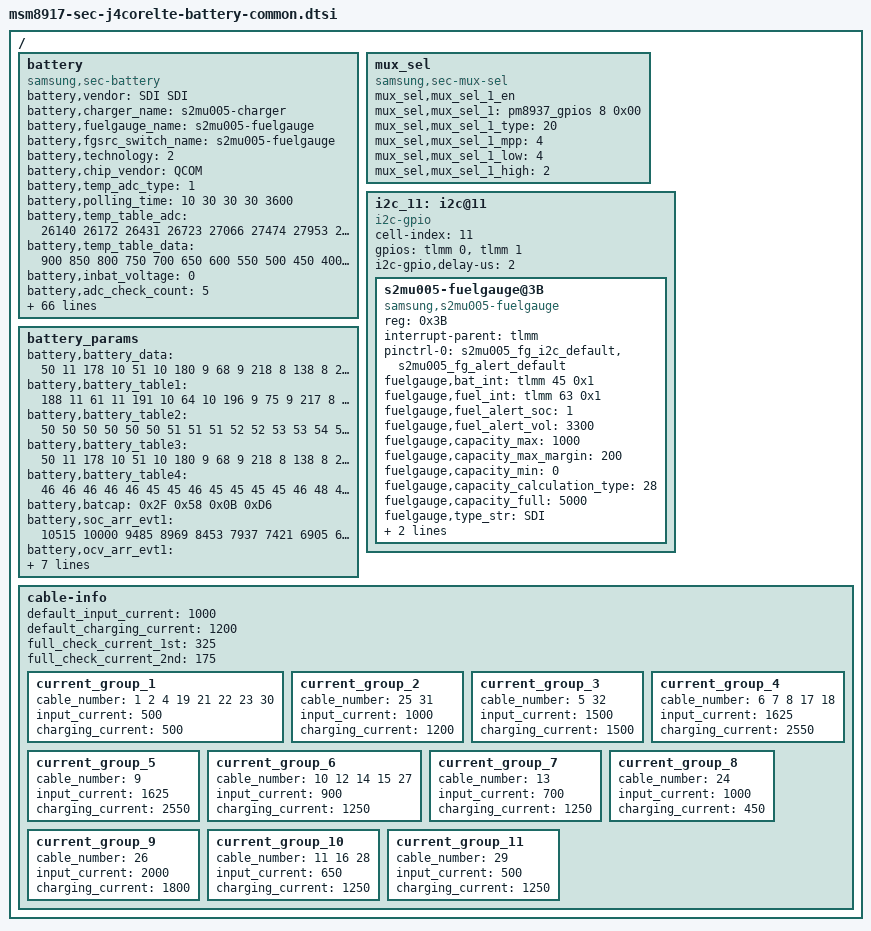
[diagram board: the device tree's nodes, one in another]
/* Copyright (c) 2015, The Linux Foundation. All rights reserved.
 *
 * This program is free software; you can redistribute it and/or modify
 * it under the terms of the GNU General Public License version 2 and
 * only version 2 as published by the Free Software Foundation.
 *
 * This program is distributed in the hope that it will be useful,
 * but WITHOUT ANY WARRANTY; without even the implied warranty of
 * MERCHANTABILITY or FITNESS FOR A PARTICULAR PURPOSE.  See the
 * GNU General Public License for more details.
 */

/ {
	battery {
		status = "okay";
		compatible = "samsung,sec-battery";
		battery,vendor = "SDI SDI";
		battery,charger_name = "s2mu005-charger";
		battery,fuelgauge_name = "s2mu005-fuelgauge";
		battery,fgsrc_switch_name = "s2mu005-fuelgauge"; /* Fuelgauge voltage source */
		battery,technology = <2>; /* POWER_SUPPLY_TECHNOLOGY_LION */
		battery,chip_vendor = "QCOM";
		
		battery,temp_adc_type = <1>; /* SEC_BATTERY_ADC_TYPE_AP */

		battery,polling_time = <10 30 30 30 3600>;

		battery,temp_table_adc = <26140 26172 26431 26723 27066 27474 27953 28492 29136 29862 30583 31973 32751 33835 34847 35867 36897 37876 38713 39527 40193 40751 41156>;
		battery,temp_table_data = <900 850 800 750 700 650 600 550 500 450 400 350 300 250 200 150 100 50 0 (-50) (-100) (-150) (-200)>;

		battery,inbat_voltage = <0>;

		battery,adc_check_count = <5>;

		battery,cable_check_type = <4>; /* SEC_BATTERY_CABLE_CHECK_PSY */
		battery,cable_source_type = <1>; /* SEC_BATTERY_CABLE_SOURCE_EXTERNAL */
		battery,polling_type = <1>; /* SEC_BATTERY_MONITOR_ALARM */
		battery,monitor_initial_count = <0>;

		battery,battery_check_type = <0>; /* SEC_BATTERY_CHECK_NONE */
		battery,check_count = <0>;

		battery,check_adc_max = <1440>;
		battery,check_adc_min = <0>;

		battery,ovp_uvlo_check_type = <3>; /* SEC_BATTERY_OVP_UVLO_CHGPOLLING */

		battery,thermal_source = <2>; /* SEC_BATTERY_THERMAL_SOURCE_ADC */
		battery,chg_thermal_source = <0>;
		battery,chg_temp_check = <0>;

		battery,adc_channels = <0x13>;
		battery,channel_names = "adc-temp";
		battery,channel_cells = <1>;

		battery,temp_check_type = <2>; /* SEC_BATTERY_TEMP_CHECK_TEMP */
		battery,temp_check_count = <1>;
		battery,temp_highlimit_threshold_normal = <800>;
		battery,temp_highlimit_recovery_normal = <750>;
		battery,temp_high_threshold_normal = <500>;
		battery,temp_high_recovery_normal = <450>;
		battery,temp_low_threshold_normal = <0>;
		battery,temp_low_recovery_normal = <50>;
		battery,temp_highlimit_threshold_lpm = <800>;
		battery,temp_highlimit_recovery_lpm = <750>;
		battery,temp_high_threshold_lpm = <500>;
		battery,temp_high_recovery_lpm = <450>;
		battery,temp_low_threshold_lpm = <0>;
		battery,temp_low_recovery_lpm = <50>;

		battery,full_check_type = <2>; /* SEC_BATTERY_FULLCHARGED_FG_CURRENT */
		battery,full_check_type_2nd = <2>; /* SEC_BATTERY_FULLCHARGED_FG_CURRENT */
		battery,full_check_count = <1>;
		battery,chg_gpio_full_check = <0>;
		battery,chg_polarity_full_check = <1>;

		/* SEC_BATTERY_FULL_CONDITION_SOC |
		   SEC_BATTERY_FULL_CONDITION_NOTIMEFULL |
		   SEC_BATTERY_FULL_CONDITION_VCELL */
		battery,full_condition_type = <13>;
		battery,full_condition_soc = <93>;
		battery,full_condition_vcell = <4290>;

		battery,recharge_check_count = <2>;
		battery,recharge_condition_type = <4>; /* SEC_BATTERY_RECHARGE_CONDITION_VCELL */
		battery,recharge_condition_soc = <98>;
		battery,recharge_condition_vcell = <4250>;

		battery,expired_time = <18600>;      /* 230min + 80min margin */
		battery,recharging_expired_time = <5400>;
		battery,standard_curr = <1034>; /* IP < CP */

		battery,swelling_high_temp_block = <410>;
		battery,swelling_high_temp_recov = <390>;

		battery,swelling_low_temp_2step_mode = <1>;
		battery,swelling_low_temp_block_1st = <150>;
		battery,swelling_low_temp_recov_1st = <200>;
		battery,swelling_low_temp_block_2nd = <50>;
		battery,swelling_low_temp_recov_2nd = <100>;

		battery,swelling_low_temp_current = <750>;	/* 0.3C */
		battery,swelling_low_temp_topoff = <175>;	/* 0.05C */
		battery,swelling_high_temp_current = <1150>;	/* 0.45C */
		battery,swelling_high_temp_topoff = <175>;	/* 0.05C */

		battery,swelling_drop_float_voltage = <4150>;
		battery,swelling_high_rechg_voltage = <4000>;
		battery,swelling_low_rechg_voltage = <4000>;

		battery,siop_input_limit_current = <1000>;
		battery,siop_charging_limit_current = <1000>;

		battery,chg_float_voltage = <4350>;
		battery,mivr_voltage = <1>; /* 0:  4200, 1 : 4300, 2 : 4400 ..... 7: 4900 */

		battery,cisd_max_voltage_thr = <5000>;

		/* cycle(week), chg_float_voltage, recharge_condition_vcell, full_condition_vcell, full_condition_soc*/
		battery,age_data = <0 4350 4250 4250 93	/*4.35*/
				200 4330 4230 4230 92	/*4.33*/
				250 4310 4210 4210 91	/*4.31*/
				300 4290 4190 4190 90	/*4.29*/
				1000 4240 4140 4140 89	/*4.24*/
				>;

		qcom,sec-battery-vadc = <&pm8937_vadc>;
	};


	mux_sel {
		compatible = "samsung,sec-mux-sel";
		mux_sel,mux_sel_1_en;
		mux_sel,mux_sel_1 = <&pm8937_gpios 8 0x00>;
		mux_sel,mux_sel_1_type = <20>; /* BATT_THM_MUX_SEL | AP_THM_MUX_SEL */
		mux_sel,mux_sel_1_mpp = <4>; /* SEC_MPP4_MUX_SEL */
		mux_sel,mux_sel_1_low = <4>; /* SEC_MUX_SEL_AP_THM */
		mux_sel,mux_sel_1_high = <2>; /* SEC_MUX_SEL_BATT_THM */
	};

	i2c_11: i2c@11 {
		cell-index = <11>;
		compatible = "i2c-gpio";
		gpios = <&tlmm 0 0	/* sda */
			&tlmm 1 0	/* scl */
			>;
		i2c-gpio,delay-us = <2>;
		#address-cells = <1>;
		#size-cells = <0>;

		s2mu005-fuelgauge@3B{
			status = "okay";
			compatible = "samsung,s2mu005-fuelgauge";
			reg = <0x3B>;
			interrupt-parent = <&tlmm>;
			pinctrl-names = "default";
			pinctrl-0 = <&s2mu005_fg_i2c_default &s2mu005_fg_alert_default>;
			fuelgauge,bat_int = <&tlmm 45 0x1>;
			fuelgauge,fuel_int = <&tlmm 63 0x1>;
			fuelgauge,fuel_alert_soc = <1>;
			fuelgauge,fuel_alert_vol = <3300>;
			fuelgauge,capacity_max = <1000>;
			fuelgauge,capacity_max_margin = <200>;
			fuelgauge,capacity_min = <0>;
			fuelgauge,capacity_calculation_type = <28>;
			fuelgauge,capacity_full = <5000>; /* battery capacity */
			fuelgauge,type_str = "SDI";
			fuelgauge,model_type = <1>;
			fuelgauge,fg_log_enable = <1>;
		};
	};
	
	battery_params {
			battery,battery_data =
			<
				/***** battery data for 4.35 *****/
				/* battery,battery_table3 */
				50 11 178 10 51 10 180 9 68 9
				218 8 138 8 247 7 190 7 116 7
				11 7 194 6 146 6 109 6 80 6
				57 6 32 6 247 5 190 5 133 5
				54 5 235 0 235 8 124 8 13 8
				158 7 47 7 192 6 80 6 225 5
				114 5 3 5 148 4 37 4 181 3
				70 3 215 2 104 2 249 1 137 1
				26 1 171 0 60 0 205 15

				/* battery,battery_table4 */
				46 46 46 46 46 45 45 46 45 45
				45 45 46 48 49 51 53 55 60 71
				83 93

				/* battery,batcap */
				0x2F 0x58 0x0B 0xD6 /* [0x0F] [0x0E] [0x11] [0x10] */
				/* battery,accum */
				0xE1 0x07 /* [0x44] [0x45] */

				/* battery,soc_arr_val */
				11150 10607 10064 9521 8978 8436 7893 7350 6807 6264 5721 5179 4636 4093 3550 3007 2464 1921 1379 835 293 (-250)
				/* battery,ocv_arr_val */
				43992 43371 42750 42130 41582 41063 40673 39956 39679 39319 38802 38447 38213 38034 37891 37777 37656 37455 37179 36900 36516 31150

				/***** battery data for 4.33 *****/
				/* battery,battery_table3 */
				95 11 220 10 89 10 215 9 100 9
				248 8 145 8 29 8 193 7 134 7
				46 7 210 6 158 6 119 6 88 6
				62 6 30 6 246 5 192 5 144 5
				3 5 135 1 167 8 59 8 208 7
				100 7 249 6 141 6 34 6 182 5
				75 5 223 4 116 4 8 4 157 3
				49 3 198 2 90 2 239 1 131 1
				24 1 172 0 65 0 213 15

				/* battery,battery_table4 */
				49 49 49 49 49 49 49 49 49 48
				48 48 49 49 50 52 53 55 57 59
				68 145

				/* battery,batcap */
				0x32 0xB4 0x0C 0xAD /* [0x0F] [0x0E] [0x11] [0x10] */
				/* battery,accum */
				0xc3 0x7 /* [0x44] [0x45] */

				/* battery,soc_arr_val */
				10814 10290 9765 9240 8715 8189 7665 7140 6615 6090 5565 5040 4516 3991 3466 2940 2416 1891 1366 840 316 (-208)
				/* battery,ocv_arr_val */
				44212 43573 42934 42300 41739 41209 40706 40144 39691 39403 38974 38527 38270 38080 37929 37803 37647 37453 37188 36955 36263 31907

				/***** battery data for 4.31 *****/
				/* battery,battery_table3 */
				45 11 175 10 50 10 181 9 70 9
				221 8 127 8 253 7 186 7 117 7
				26 7 200 6 151 6 114 6 85 6
				59 6 27 6 244 5 190 5 144 5
				2 5 112 1 173 8 65 8 213 7
				105 7 254 6 146 6 38 6 186 5
				78 5 226 4 118 4 10 4 159 3
				51 3 199 2 91 2 239 1 131 1
				24 1 172 0 64 0 212 15

				/* battery,battery_table4 */
				48 48 49 49 49 49 48 48 48 48
				47 48 48 49 50 51 52 54 57 60
				69 156

				/* battery,batcap */
				0x31 0xEC 0x0C 0x7B /* [0x0F] [0x0E] [0x11] [0x10] */
				/* battery,accum */
				0xc3 0x7 /* [0x44] [0x45] */

				/* battery,soc_arr_val */
				10845 10318 9791 9265 8738 8211 7685 7158 6631 6105 5578 5051 4525 3998 3472 2945 2418 1892 1365 838 312 (-214)
				/* battery,ocv_arr_val */
				43970 43356 42742 42133 41590 41080 40621 39987 39657 39323 38878 38476 38238 38058 37914 37790 37633 37440 37176 36952 36259 31798

				/***** battery data for 4.29 *****/
				/* battery,battery_table3 */
				254 10 133 10 12 10 147 9 39 9
				194 8 109 8 229 7 176 7 100 7
				8 7 190 6 145 6 110 6 81 6
				57 6 26 6 243 5 189 5 144 5
				9 5 160 1 172 8 64 8 213 7
				105 7 253 6 145 6 37 6 186 5
				78 5 226 4 118 4 10 4 159 3
				51 3 199 2 91 2 240 1 132 1
				24 1 172 0 64 0 213 15

				/* battery,battery_table4 */
				101 101 100 99 100 100 99 99 99 98
				99 99 99 100 102 104 106 109 113 120
				132 178

				/* battery,batcap */
				0x31 0x24 0x0C 0x49 /* [0x0F] [0x0E] [0x11] [0x10] */
				/* battery,accum */
				0xc3 0x7 /* [0x44] [0x45] */

				/* battery,soc_arr_val */
				10841 10315 9789 9262 8736 8210 7683 7157 6631 6104 5578 5051 4525 3999 3472 2945 2420 1893 1366 840 314 (-212)
				/* battery,ocv_arr_val */
				43742 43150 42558 41968 41441 40949 40533 39869 39610 39239 38787 38429 38207 38035 37898 37779 37627 37436 37172 36953 36293 32032

				/***** battery data for 4.24 *****/
				/* battery,battery_table3 */
				135 10 24 10 169 9 58 9 215 8
				133 8 1 8 191 7 135 7 54 7
				220 6 167 6 129 6 99 6 74 6
				49 6 17 6 233 5 178 5 138 5
				243 4 135 1 170 8 63 8 211 7
				103 7 251 6 144 6 36 6 184 5
				77 5 225 4 117 4 9 4 158 3
				50 3 198 2 91 2 239 1 131 1
				24 1 172 0 64 0 212 15

				/* battery,battery_table4 */
				95 95 95 95 95 95 95 95 94 94
				95 95 96 97 98 99 102 105 108 115
				129 180

				/* battery,batcap */
				0x2E 0xE0 0x0B 0xB8 /* [0x0F] [0x0E] [0x11] [0x10] */
				/* battery,accum */
				0xE0 0x7 /* [0x44] [0x45] */

				/* battery,soc_arr_val */
				10832 10306 9780 9254 8728 8202 7675 7150 6624 6098 5572 5046 4521 3995 3469 2943 2417 1891 1365 839 313 (-213)
				/* battery,ocv_arr_val */
				43157 42615 42073 41532 41051 40648 40007 39682 39407 39014 38572 38318 38130 37982 37861 37740 37581 37386 37121 36925 36189 31910
			>;
			battery,battery_table1 = <188 11 61 11 191 10 64 10 196 9
					75 9 217 8 110 8 13 8 173 7
					66 7 235 6 177 6 132 6 96 6
					67 6 31 6 242 5 164 5 124 5
					23 5 144 1 216 8 105 8 251 7
					141 7 30 7 176 6 65 6 211 5
					101 5 246 4 136 4 25 4 171 3
					60 3 206 2 95 2 241 1 131 1
					20 1 166 0 55 0 201 15>;

			battery,battery_table2 = <50 50 50 50 50 50 51 51 51 52
					52 53 53 54 54 55 55 56 57 59
					63 154>;

			battery,battery_table3 = <50 11 178 10 51 10 180 9 68 9
					218 8 138 8 247 7 190 7 116 7
					11 7 194 6 146 6 109 6 80 6
					57 6 32 6 247 5 190 5 133 5
					54 5 235 0 235 8 124 8 13 8
					158 7 47 7 192 6 80 6 225 5
					114 5 3 5 148 4 37 4 181 3
					70 3 215 2 104 2 249 1 137 1
					26 1 171 0 60 0 205 15>;

			battery,battery_table4 = <46 46 46 46 46 45 45 46 45 45
					45 45 46 48 49 51 53 55 60 71
					83 93>;

			battery,batcap = <0x2F 0x58 0x0B 0xD6>; /* [0x0F] [0x0E] [0x11] [0x10] */

			battery,soc_arr_evt1 = <10515 10000 9485 8969 8453 7937 7421 6905 6389 5873 5358 4842 4326 3810 3294 2778 2263 1747 1231 716 200 (-269)>;
			battery,ocv_arr_evt1 = <44051 43459 42867 42288 41716 41175 40664 40199 39779 39268 38784 38482 38250 38059 37906 37778 37594 37368 36957 36835 36289 31955>;

			battery,soc_arr_evt2 = <11150 10607 10064 9521 8978 8436 7893 7350 6807 6264 5721 5179 4636 4093 3550 3007 2464 1921 1379 835 293 (-250)>;
			battery,ocv_arr_evt2 = <43992 43371 42750 42130 41582 41063 40673 39956 39679 39319 38802 38447 38213 38034 37891 37777 37656 37455 37179 36900 36516 31150>;
			
			battery,FG_Accumulative_rate_evt2 =<0xE1 0x07>;
			battery,data_ver = <0x02>;
	};
	
	/* sec_battery_cable
 *   0	UNKNOWN,
 *   1	NONE,
 *   2	PREPARE_TA,
 *   3	TA,
 *   4	USB,
 *   5	USB_CDP,
 *   6	9V_TA,
 *   7	9V_ERR,
 *   8	9V_UNKNOWN,
 *   9	12V_TA,
 *  10	WIRELESS,
 *  11	HV_WIRELESS,
 *  12	PMA_WIRELESS,
 *  13	WIRELESS_PACK,
 *  14	WIRELESS_PACK_TA,
 *  15	WIRELESS_STAND,
 *  16	WIRELESS_HV_STAND,
 *  17	QC20,
 *  18	QC30,
 *  19	PDIC,
 *  20	UARTOFF,
 *  21	OTG,
 *  22	LAN_HUB,
 *  23	POWER_SHARING,
 *  24	HMT_CONNECTED,
 *  25	HMT_CHARGE,
 *  26	HV_TA_CHG_LIMIT,
 *  27	WIRELESS_VEHICLE,
 *  28	WIRELESS_HV_VEHICLE,
 *  29	PREPARE_WIRELESS_HV,
 *  30  TIMEOUT,
 *  31  SMART_OTG,
 *  32  SMART_NOTG,
 *  33	CABLE_MAX,
 */
	cable-info {
		default_input_current = <1000>;
		default_charging_current = <1200>;
		full_check_current_1st = <325>;
		full_check_current_2nd = <175>;
		current_group_1 {
			cable_number = <1 2 4 19 21 22 23 30>;
			input_current = <500>;
			charging_current = <500>;
		};
		current_group_2 {
			cable_number = <25 31>;
			input_current = <1000>;
			charging_current = <1200>;
		};
		current_group_3 {
			cable_number = <5 32>;
			input_current = <1500>;
			charging_current = <1500>;
		};
		current_group_4 {
			cable_number = <6 7 8 17 18>;
			input_current = <1625>;
			charging_current = <2550>;
		};
		current_group_5 {
			cable_number = <9>;
			input_current = <1625>;
			charging_current = <2550>;
		};
		current_group_6 {
			cable_number = <10 12 14 15 27>;
			input_current = <900>;
			charging_current = <1250>;
		};
		current_group_7 {
			cable_number = <13>;
			input_current = <700>;
			charging_current = <1250>;
		};
		current_group_8 {
			cable_number = <24>;
			input_current = <1000>;
			charging_current = <450>;
		};
		current_group_9 {
			cable_number = <26>;
			input_current = <2000>;
			charging_current = <1800>;
		};
		current_group_10 {
			cable_number = <11 16 28>;
			input_current = <650>;
			charging_current = <1250>;
		};
		current_group_11 {
			cable_number = <29>;
			input_current = <500>;
			charging_current = <1250>;
		};
	};
};
